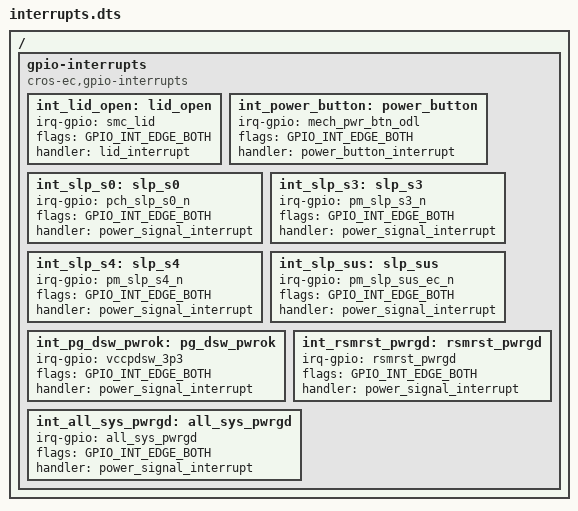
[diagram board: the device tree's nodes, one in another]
/* Copyright 2022 The Chromium OS Authors. All rights reserved.
 * Use of this source code is governed by a BSD-style license that can be
 * found in the LICENSE file.
 */
/ {
	gpio-interrupts {
		compatible = "cros-ec,gpio-interrupts";

		int_lid_open: lid_open {
			irq-gpio = <&smc_lid>;
			flags = <GPIO_INT_EDGE_BOTH>;
			handler = "lid_interrupt";
		};
		int_power_button: power_button {
			irq-gpio = <&mech_pwr_btn_odl>;
			flags = <GPIO_INT_EDGE_BOTH>;
			handler = "power_button_interrupt";
		};
		int_slp_s0: slp_s0 {
			irq-gpio = <&pch_slp_s0_n>;
			flags = <GPIO_INT_EDGE_BOTH>;
			handler = "power_signal_interrupt";
		};
		int_slp_s3: slp_s3 {
			irq-gpio = <&pm_slp_s3_n>;
			flags = <GPIO_INT_EDGE_BOTH>;
			handler = "power_signal_interrupt";
		};
		int_slp_s4: slp_s4 {
			irq-gpio = <&pm_slp_s4_n>;
			flags = <GPIO_INT_EDGE_BOTH>;
			handler = "power_signal_interrupt";
		};
		int_slp_sus: slp_sus {
			irq-gpio = <&pm_slp_sus_ec_n>;
			flags = <GPIO_INT_EDGE_BOTH>;
			handler = "power_signal_interrupt";
		};
		int_pg_dsw_pwrok: pg_dsw_pwrok {
			irq-gpio = <&vccpdsw_3p3>;
			flags = <GPIO_INT_EDGE_BOTH>;
			handler = "power_signal_interrupt";
		};
		int_rsmrst_pwrgd: rsmrst_pwrgd {
			irq-gpio = <&rsmrst_pwrgd>;
			flags = <GPIO_INT_EDGE_BOTH>;
			handler = "power_signal_interrupt";
		};
		int_all_sys_pwrgd: all_sys_pwrgd {
			irq-gpio = <&all_sys_pwrgd>;
			flags = <GPIO_INT_EDGE_BOTH>;
			handler = "power_signal_interrupt";
		};
	};
};
